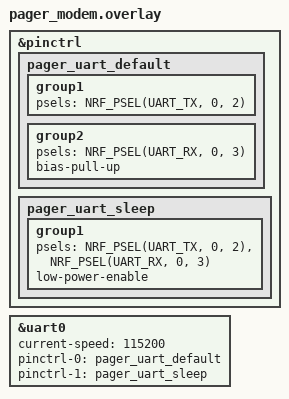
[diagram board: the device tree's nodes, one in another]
/*
 * Devicetree overlay for Nordic's Serial Modem application on the Makerdiary nRF9151
 * Connect Kit, so that it talks to the pager's XIAO instead of the kit's USB bridge.
 * Keep in step with hardware/netlist.yaml (U2).
 *
 *   P0.02  UART TX  -> XIAO D5 (RX)
 *   P0.03  UART RX  <- XIAO D4 (TX)
 *
 * Only two signal wires: the EN05 leaves no spare pin for DTR / RI or a power switch, so the modem
 * stays powered and the pager idles it with AT+CFUN=0.
 *
 * VERIFY: node labels differ between Serial Modem releases. Start from the `external-mcu` overlay
 * that ships with the version you build, change only the pin numbers to the ones above, and turn
 * off its DTR/RI options.
 */
&pinctrl {
	pager_uart_default: pager_uart_default {
		group1 {
			psels = <NRF_PSEL(UART_TX, 0, 2)>;
		};
		group2 {
			psels = <NRF_PSEL(UART_RX, 0, 3)>;
			bias-pull-up;
		};
	};
	pager_uart_sleep: pager_uart_sleep {
		group1 {
			psels = <NRF_PSEL(UART_TX, 0, 2)>, <NRF_PSEL(UART_RX, 0, 3)>;
			low-power-enable;
		};
	};
};

&uart0 {
	status = "okay";
	current-speed = <115200>;
	/delete-property/ hw-flow-control;
	pinctrl-0 = <&pager_uart_default>;
	pinctrl-1 = <&pager_uart_sleep>;
	pinctrl-names = "default", "sleep";
};
